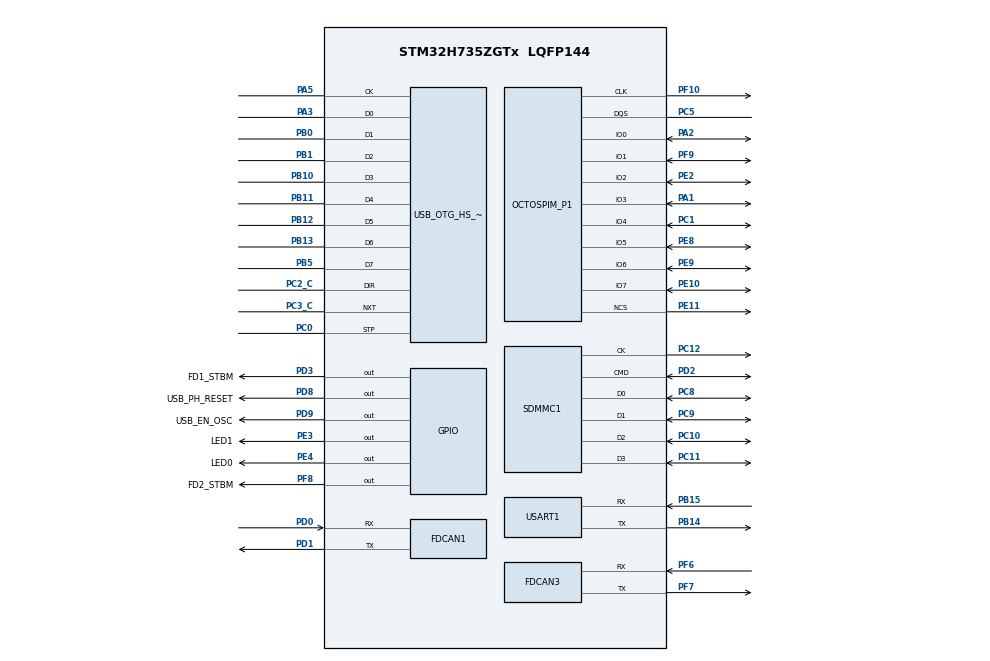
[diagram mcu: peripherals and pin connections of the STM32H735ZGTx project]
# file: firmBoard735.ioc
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CORTEX_M7.default_mode_Activation=1
Dma.Request0=USART1_TX
Dma.USART1_TX.0.Direction=DMA_MEMORY_TO_PERIPH
Dma.USART1_TX.0.EventEnable=DISABLE
Dma.USART1_TX.0.FIFOMode=DMA_FIFOMODE_DISABLE
Dma.USART1_TX.0.Instance=DMA1_Stream0
Dma.USART1_TX.0.MemDataAlignment=DMA_MDATAALIGN_BYTE
Dma.USART1_TX.0.MemInc=DMA_MINC_ENABLE
Dma.USART1_TX.0.Mode=DMA_NORMAL
Dma.USART1_TX.0.PeriphDataAlignment=DMA_PDATAALIGN_BYTE
Dma.USART1_TX.0.PeriphInc=DMA_PINC_DISABLE
Dma.USART1_TX.0.Polarity=HAL_DMAMUX_REQ_GEN_RISING
Dma.USART1_TX.0.Priority=DMA_PRIORITY_LOW
Dma.USART1_TX.0.RequestNumber=1
Dma.USART1_TX.0.SignalID=NONE
Dma.USART1_TX.0.SyncEnable=DISABLE
Dma.USART1_TX.0.SyncPolarity=HAL_DMAMUX_SYNC_NO_EVENT
Dma.USART1_TX.0.SyncRequestNumber=1
Dma.USART1_TX.0.SyncSignalID=NONE
FATFS.USE_DMA_CODE_SD=1
FATFS._FS_NORTC=0
FATFS._USE_FASTSEEK=0
FATFS._USE_LFN=1
FATFS._USE_MKFS=0
FDCAN1.CalculateBaudRateNominal=500000
FDCAN1.CalculateTimeBitNominal=2000
FDCAN1.CalculateTimeQuantumNominal=125.0
FDCAN1.Mode=FDCAN_MODE_BUS_MONITORING
FDCAN1.NominalPrescaler=12
FDCAN1.NominalSyncJumpWidth=2
FDCAN1.NominalTimeSeg1=13
FDCAN1.NominalTimeSeg2=2
FDCAN1.RxFifo0ElmtsNbr=64
FDCAN1.StdFiltersNbr=0
FDCAN1.TxFifoQueueElmtsNbr=0
FDCAN3.AutoRetransmission=ENABLE
FDCAN3.CalculateBaudRateNominal=6000000
FDCAN3.CalculateTimeBitNominal=166
FDCAN3.CalculateTimeQuantumNominal=10.416666666666666
FDCAN3.DataTimeSeg1=1
FDCAN3.DataTimeSeg2=1
FDCAN3.MessageRAMOffset=256
FDCAN3.Mode=FDCAN_MODE_NORMAL
FDCAN3.NominalPrescaler=1
FDCAN3.NominalTimeSeg1=13
FDCAN3.NominalTimeSeg2=2
FDCAN3.RxFifo0ElmtsNbr=1
FDCAN3.StdFiltersNbr=1
FDCAN3.TxFifoQueueElmtsNbr=1
Mcu.Family=STM32H7
Mcu.Name=STM32H735ZGTx
Mcu.Package=LQFP144
NVIC.DMA1_Stream0_IRQn=true\:0\:0\:false\:false\:true\:false\:true\:true
NVIC.OTG_HS_EP1_IN_IRQn=true\:0\:0\:false\:false\:true\:true\:true\:true
NVIC.OTG_HS_EP1_OUT_IRQn=true\:0\:0\:false\:false\:true\:true\:true\:true
NVIC.OTG_HS_IRQn=true\:0\:0\:false\:false\:true\:true\:true\:true
NVIC.PriorityGroup=NVIC_PRIORITYGROUP_4
NVIC.SDMMC1_IRQn=true\:0\:0\:false\:false\:true\:true\:true\:true
NVIC.USART1_IRQn=true\:0\:0\:false\:false\:true\:true\:true\:true
OCTOSPI1.AccessTime=6
OCTOSPI1.ChipSelectBoundary=0
OCTOSPI1.ChipSelectHighTime=8
OCTOSPI1.ClockPrescaler=11
OCTOSPI1.DelayBlockBypass=HAL_OSPI_DELAY_BLOCK_USED
OCTOSPI1.DelayHoldQuarterCycle=HAL_OSPI_DHQC_ENABLE
OCTOSPI1.DeviceSize=23
OCTOSPI1.FifoThreshold=4
OCTOSPI1.LatencyMode=HAL_OSPI_FIXED_LATENCY
OCTOSPI1.RWRecoveryTime=3
OCTOSPI1.Refresh=99
OCTOSPI1.WriteZeroLatency=HAL_OSPI_LATENCY_ON_WRITE
PA1.Mode=OCTOSPI1_IOL_Port1L
PA1.Signal=OCTOSPIM_P1_IO3
PA13(JTMS/SWDIO).Mode=JTAG_5_pins
PA13(JTMS/SWDIO).Signal=DEBUG_JTMS-SWDIO
PA14(JTCK/SWCLK).Mode=JTAG_5_pins
PA14(JTCK/SWCLK).Signal=DEBUG_JTCK-SWCLK
PA15(JTDI).Mode=JTAG_5_pins
PA15(JTDI).Signal=DEBUG_JTDI
PA2.Mode=OCTOSPI1_IOL_Port1L
PA2.Signal=OCTOSPIM_P1_IO0
PA3.GPIO_Speed=GPIO_SPEED_FREQ_VERY_HIGH
PA3.Mode=Device_HS
PA3.Signal=USB_OTG_HS_ULPI_D0
PA5.GPIO_Speed=GPIO_SPEED_FREQ_VERY_HIGH
PA5.Mode=Device_HS
PA5.Signal=USB_OTG_HS_ULPI_CK
PB0.GPIO_Speed=GPIO_SPEED_FREQ_VERY_HIGH
PB0.Mode=Device_HS
PB0.Signal=USB_OTG_HS_ULPI_D1
PB1.GPIO_Speed=GPIO_SPEED_FREQ_VERY_HIGH
PB1.GPIO_Speed_Only_High=GPIO_SPEED_FREQ_VERY_HIGH
PB1.Mode=Device_HS
PB1.Signal=USB_OTG_HS_ULPI_D2
PB10.GPIO_Speed=GPIO_SPEED_FREQ_VERY_HIGH
PB10.Mode=Device_HS
PB10.Signal=USB_OTG_HS_ULPI_D3
PB11.GPIO_Speed=GPIO_SPEED_FREQ_VERY_HIGH
PB11.Mode=Device_HS
PB11.Signal=USB_OTG_HS_ULPI_D4
PB12.GPIO_Speed=GPIO_SPEED_FREQ_VERY_HIGH
PB12.Mode=Device_HS
PB12.Signal=USB_OTG_HS_ULPI_D5
PB13.GPIO_Speed=GPIO_SPEED_FREQ_VERY_HIGH
PB13.Mode=Device_HS
PB13.Signal=USB_OTG_HS_ULPI_D6
PB14.Mode=Asynchronous
PB14.Signal=USART1_TX
PB15.Mode=Asynchronous
PB15.Signal=USART1_RX
PB3(JTDO/TRACESWO).Mode=JTAG_5_pins
PB3(JTDO/TRACESWO).Signal=DEBUG_JTDO-SWO
PB4(NJTRST).Mode=JTAG_5_pins
PB4(NJTRST).Signal=DEBUG_JTRST
PB5.GPIO_Speed=GPIO_SPEED_FREQ_VERY_HIGH
PB5.Mode=Device_HS
PB5.Signal=USB_OTG_HS_ULPI_D7
PC0.GPIO_Speed=GPIO_SPEED_FREQ_VERY_HIGH
PC0.Mode=Device_HS
PC0.Signal=USB_OTG_HS_ULPI_STP
PC1.Mode=OCTOSPI1_IOH_Port1H
PC1.Signal=OCTOSPIM_P1_IO4
PC10.Mode=SD_4_bits_Wide_bus
PC10.Signal=SDMMC1_D2
PC11.Mode=SD_4_bits_Wide_bus
PC11.Signal=SDMMC1_D3
PC12.Mode=SD_4_bits_Wide_bus
PC12.Signal=SDMMC1_CK
PC14-OSC32_IN.Mode=LSE-External-Oscillator
PC14-OSC32_IN.Signal=RCC_OSC32_IN
PC15-OSC32_OUT.Mode=LSE-External-Oscillator
PC15-OSC32_OUT.Signal=RCC_OSC32_OUT
PC2_C.GPIO_Speed=GPIO_SPEED_FREQ_VERY_HIGH
PC2_C.Mode=Device_HS
PC2_C.Signal=USB_OTG_HS_ULPI_DIR
PC3_C.GPIO_Speed=GPIO_SPEED_FREQ_VERY_HIGH
PC3_C.Mode=Device_HS
PC3_C.Signal=USB_OTG_HS_ULPI_NXT
PC5.Mode=OCTOSPI1_Port1_DQS
PC5.Signal=OCTOSPIM_P1_DQS
PC8.Mode=SD_4_bits_Wide_bus
PC8.Signal=SDMMC1_D0
PC9.Mode=SD_4_bits_Wide_bus
PC9.Signal=SDMMC1_D1
PD0.Mode=FDCAN_Activate
PD0.Signal=FDCAN1_RX
PD1.Mode=FDCAN_Activate
PD1.Signal=FDCAN1_TX
PD2.Mode=SD_4_bits_Wide_bus
PD2.Signal=SDMMC1_CMD
PD3.GPIO_Label=FD1_STBM
PD3.Signal=GPIO_Output
PD8.GPIO_Label=USB_PH_RESET
PD8.Signal=GPIO_Output
PD9.GPIO_Label=USB_EN_OSC
PD9.Signal=GPIO_Output
PE10.Mode=OCTOSPI1_IOH_Port1H
PE10.Signal=OCTOSPIM_P1_IO7
PE11.Mode=OCTOSPI1_Port1_NCS
PE11.Signal=OCTOSPIM_P1_NCS
PE2.Mode=OCTOSPI1_IOL_Port1L
PE2.Signal=OCTOSPIM_P1_IO2
PE3.GPIO_Label=LED1
PE3.Signal=GPIO_Output
PE4.GPIO_Label=LED0
PE4.Signal=GPIO_Output
PE8.Mode=OCTOSPI1_IOH_Port1H
PE8.Signal=OCTOSPIM_P1_IO5
PE9.Mode=OCTOSPI1_IOH_Port1H
PE9.Signal=OCTOSPIM_P1_IO6
PF10.Mode=O1_P1_CLK
PF10.Signal=OCTOSPIM_P1_CLK
PF6.Mode=FDCAN_Activate
PF6.Signal=FDCAN3_RX
PF7.Mode=FDCAN_Activate
PF7.Signal=FDCAN3_TX
PF8.GPIO_Label=FD2_STBM
PF8.Signal=GPIO_Output
PF9.Mode=OCTOSPI1_IOL_Port1L
PF9.Signal=OCTOSPIM_P1_IO1
PH0-OSC_IN.Mode=HSE-External-Oscillator
PH0-OSC_IN.Signal=RCC_OSC_IN
PH1-OSC_OUT.Mode=HSE-External-Oscillator
PH1-OSC_OUT.Signal=RCC_OSC_OUT
ProjectManager.HeapSize=0x200
ProjectManager.StackSize=0x400
ProjectManager.TargetToolchain=STM32CubeIDE
RCC.ADCFreq_Value=96000000
RCC.APB1Freq_Value=132000000
RCC.APB2Freq_Value=132000000
RCC.APB3Freq_Value=132000000
RCC.APB4Freq_Value=132000000
RCC.CortexFreq_Value=528000000
RCC.D1PPRE=RCC_APB3_DIV2
RCC.D2PPRE1=RCC_APB1_DIV2
RCC.D2PPRE2=RCC_APB2_DIV2
RCC.D3PPRE=RCC_APB4_DIV2
RCC.DIVM1=1
RCC.DIVM2=1
RCC.DIVN1=66
RCC.DIVN2=24
RCC.DIVP1=1
RCC.DIVQ1=11
RCC.DIVR2=2
RCC.FDCANCLockSelection=RCC_FDCANCLKSOURCE_PLL2
RCC.HCLKFreq_Value=264000000
RCC.HPRE=RCC_HCLK_DIV2
RCC.HSE_VALUE=8000000
RCC.PLL2FRACN=0
RCC.PLL3FRACN=0
RCC.PLLFRACN=0
RCC.PLLSourceVirtual=RCC_PLLSOURCE_HSE
RCC.RTCClockSelection=RCC_RTCCLKSOURCE_LSE
RCC.SDMMC1CLockSelection=RCC_SDMMCCLKSOURCE_PLL2
RCC.SYSCLKFreq_VALUE=528000000
RCC.SYSCLKSource=RCC_SYSCLKSOURCE_PLLCLK
RCC.SupplySource=PWR_LDO_SUPPLY
RCC.USBFreq_Value=48000000
SDMMC1.ClockDiv=2
SDMMC1.HardwareFlowControl=SDMMC_HARDWARE_FLOW_CONTROL_ENABLE
USART1.VirtualMode-Asynchronous=VM_ASYNC
USB_DEVICE.CLASS_NAME_HS=CDC
USB_DEVICE.VirtualMode=Cdc
USB_DEVICE.VirtualModeHS=Cdc_HS
USB_OTG_HS.VirtualMode-Device_HS=Device_HS
VP_FATFS_VS_SDIO.Mode=SDIO
VP_MEMORYMAP_VS_MEMORYMAP.Mode=CurAppReg
VP_OCTOSPI1_VS_hyperbus.Mode=hyperbus_mode
VP_RTC_VS_RTC_Activate.Mode=RTC_Enabled
VP_USB_DEVICE_VS_USB_DEVICE_CDC_HS.Mode=CDC_HS
board=custom

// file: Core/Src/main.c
/* USER CODE BEGIN Header */
/**
  ******************************************************************************
  * @file           : main.c
  * @brief          : Main program body
  ******************************************************************************
  * @attention
  *
  * Copyright (c) 2026 STMicroelectronics.
  * All rights reserved.
  *
  * This software is licensed under terms that can be found in the LICENSE file
  * in the root directory of this software component.
  * If no LICENSE file comes with this software, it is provided AS-IS.
  *
  ******************************************************************************
  */
/* USER CODE END Header */
#include "main.h"
#include "fatfs.h"
#include "usb_device.h"

/* USER CODE BEGIN Includes */
#include <stdio.h>
#include "console.h"
#include "can_sniffer.h"
#include "sd_test.h"
#include "fatfs_test.h"
#include "hyperram_test.h"
#include "hyperram_capture.h"
#include "board_id.h"
#include "rtc_test.h"
/* USER CODE END Includes */

FDCAN_HandleTypeDef hfdcan1;
FDCAN_HandleTypeDef hfdcan3;

OSPI_HandleTypeDef hospi1;

RTC_HandleTypeDef hrtc;

SD_HandleTypeDef hsd1;

UART_HandleTypeDef huart1;
DMA_HandleTypeDef hdma_usart1_tx;

void SystemClock_Config(void);
void PeriphCommonClock_Config(void);
static void MPU_Config(void);
static void MX_GPIO_Init(void);
static void MX_DMA_Init(void);
static void MX_USART1_UART_Init(void);
static void MX_FDCAN1_Init(void);
static void MX_FDCAN3_Init(void);
static void MX_SDMMC1_SD_Init(void);
static void MX_OCTOSPI1_Init(void);
static void MX_RTC_Init(void);

int main(void)
{

  /* MPU Configuration--------------------------------------------------------*/
  MPU_Config();

  /* MCU Configuration--------------------------------------------------------*/

  /* Reset of all peripherals, Initializes the Flash interface and the Systick. */
  HAL_Init();

  /* Configure the system clock */
  SystemClock_Config();

  /* Configure the peripherals common clocks */
  PeriphCommonClock_Config();

  /* USER CODE BEGIN SysInit */

  /* Compensate high-speed GPIO output impedance across process/voltage/temperature. */
  HAL_EnableCompensationCell();

  /* USER CODE END SysInit */

  /* Initialize all configured peripherals */
  MX_GPIO_Init();
  MX_DMA_Init();
  MX_USART1_UART_Init();
  MX_FDCAN1_Init();
  MX_FDCAN3_Init();
  MX_SDMMC1_SD_Init();
  MX_FATFS_Init();
  MX_OCTOSPI1_Init();
  MX_RTC_Init();
  MX_USB_DEVICE_Init();
  /* USER CODE BEGIN 2 */
  Console_Init(&huart1);
  printf("\r\nBusAnalyzerII console ready\r\n");
  printf("CPU clock    : %lu Hz\r\n",
         (unsigned long)SystemCoreClock);
  BoardID_Init();
  BoardID_Print(&huart1);

  RTC_Test(&hrtc, &huart1);

  HyperRAM_Test_Memory();

  HyperRAM_Test_ConfigRegisters();
  HyperRAM_Test_BurstStress();

  SD_Test_ReadOnly();
  FATFS_Test_ReadOnly();
  FATFS_Test_ReadWrite();
  CAN_Sniffer_Init();
  HyperRAM_Capture_Init();

  /* USER CODE END 2 */

  /* Infinite loop */
  /* USER CODE BEGIN WHILE */
  uint32_t can_stats_tick = HAL_GetTick();
  uint64_t previous_capture_cycles = 0U;
  uint32_t previous_measured_frames = 0U;
  while (1)
  {
    /* USER CODE END WHILE */

    /* USER CODE BEGIN 3 */
	CAN_Sniffer_Process();

      HyperRAM_Capture_Process();

      uint32_t now = HAL_GetTick();

      if ((now - can_stats_tick) >= 1000U)
      {
          can_stats_tick = now;
          uint64_t total_capture_cycles =
              CAN_Sniffer_GetCaptureCycles();

          uint32_t total_measured_frames =
              CAN_Sniffer_GetMeasuredFrames();

          uint64_t delta_cycles =
              total_capture_cycles - previous_capture_cycles;

          uint32_t delta_frames =
              total_measured_frames - previous_measured_frames;

          previous_capture_cycles = total_capture_cycles;
          previous_measured_frames = total_measured_frames;

          uint32_t cycles_per_frame = 0U;

          if (delta_frames > 0U)
          {
              cycles_per_frame =
                  (uint32_t)(delta_cycles / delta_frames);
          }
          printf(
              "CAN rx=%lu hram=%lu sram=%lu drop=%lu "
              "hramErr=%lu hramLost=%lu wrap=%lu "
              "fifoLost=%lu maxFIFO=%lu errors=%lu cpf=%lu\r\n",
              (unsigned long)CAN_Sniffer_GetRxCount(),
              (unsigned long)HyperRAM_Capture_GetStoredCount(),
              (unsigned long)CAN_Sniffer_GetBufferedCount(),
              (unsigned long)CAN_Sniffer_GetDroppedCount(),
              (unsigned long)HyperRAM_Capture_GetWriteErrors(),
              (unsigned long)HyperRAM_Capture_GetWriteLostFrames(),
              (unsigned long)HyperRAM_Capture_GetWrapCount(),
              (unsigned long)CAN_Sniffer_GetFifoLostEvents(),
              (unsigned long)CAN_Sniffer_GetMaxFifoFill(),
              (unsigned long)CAN_Sniffer_GetErrorCount(),
              (unsigned long)cycles_per_frame);
      }
  }
  /* USER CODE END 3 */
}

void SystemClock_Config(void)
{
  RCC_OscInitTypeDef RCC_OscInitStruct = {0};
  RCC_ClkInitTypeDef RCC_ClkInitStruct = {0};

  /** Supply configuration update enable
  */
  HAL_PWREx_ConfigSupply(PWR_LDO_SUPPLY);

  /** Configure the main internal regulator output voltage
  */
  __HAL_PWR_VOLTAGESCALING_CONFIG(PWR_REGULATOR_VOLTAGE_SCALE0);

  while(!__HAL_PWR_GET_FLAG(PWR_FLAG_VOSRDY)) {}

  /** Configure LSE Drive Capability
  */
  HAL_PWR_EnableBkUpAccess();
  __HAL_RCC_LSEDRIVE_CONFIG(RCC_LSEDRIVE_LOW);

  /** Initializes the RCC Oscillators according to the specified parameters
  * in the RCC_OscInitTypeDef structure.
  */
  RCC_OscInitStruct.OscillatorType = RCC_OSCILLATORTYPE_HSE|RCC_OSCILLATORTYPE_LSE;
  RCC_OscInitStruct.HSEState = RCC_HSE_ON;
  RCC_OscInitStruct.LSEState = RCC_LSE_ON;
  RCC_OscInitStruct.PLL.PLLState = RCC_PLL_ON;
  RCC_OscInitStruct.PLL.PLLSource = RCC_PLLSOURCE_HSE;
  RCC_OscInitStruct.PLL.PLLM = 1;
  RCC_OscInitStruct.PLL.PLLN = 66;
  RCC_OscInitStruct.PLL.PLLP = 1;
  RCC_OscInitStruct.PLL.PLLQ = 11;
  RCC_OscInitStruct.PLL.PLLR = 2;
  RCC_OscInitStruct.PLL.PLLRGE = RCC_PLL1VCIRANGE_3;
  RCC_OscInitStruct.PLL.PLLVCOSEL = RCC_PLL1VCOWIDE;
  RCC_OscInitStruct.PLL.PLLFRACN = 0;
  if (HAL_RCC_OscConfig(&RCC_OscInitStruct) != HAL_OK)
  {
    Error_Handler();
  }

  /** Initializes the CPU, AHB and APB buses clocks
  */
  RCC_ClkInitStruct.ClockType = RCC_CLOCKTYPE_HCLK|RCC_CLOCKTYPE_SYSCLK
                              |RCC_CLOCKTYPE_PCLK1|RCC_CLOCKTYPE_PCLK2
                              |RCC_CLOCKTYPE_D3PCLK1|RCC_CLOCKTYPE_D1PCLK1;
  RCC_ClkInitStruct.SYSCLKSource = RCC_SYSCLKSOURCE_PLLCLK;
  RCC_ClkInitStruct.SYSCLKDivider = RCC_SYSCLK_DIV1;
  RCC_ClkInitStruct.AHBCLKDivider = RCC_HCLK_DIV2;
  RCC_ClkInitStruct.APB3CLKDivider = RCC_APB3_DIV2;
  RCC_ClkInitStruct.APB1CLKDivider = RCC_APB1_DIV2;
  RCC_ClkInitStruct.APB2CLKDivider = RCC_APB2_DIV2;
  RCC_ClkInitStruct.APB4CLKDivider = RCC_APB4_DIV2;

  if (HAL_RCC_ClockConfig(&RCC_ClkInitStruct, FLASH_LATENCY_3) != HAL_OK)
  {
    Error_Handler();
  }
  __HAL_RCC_PLLCLKOUT_ENABLE(RCC_PLL1_DIVQ);
}

void PeriphCommonClock_Config(void)
{
  RCC_PeriphCLKInitTypeDef PeriphClkInitStruct = {0};

  /** Initializes the peripherals clock
  */
  PeriphClkInitStruct.PeriphClockSelection = RCC_PERIPHCLK_SDMMC|RCC_PERIPHCLK_FDCAN;
  PeriphClkInitStruct.PLL2.PLL2M = 1;
  PeriphClkInitStruct.PLL2.PLL2N = 24;
  PeriphClkInitStruct.PLL2.PLL2P = 2;
  PeriphClkInitStruct.PLL2.PLL2Q = 2;
  PeriphClkInitStruct.PLL2.PLL2R = 2;
  PeriphClkInitStruct.PLL2.PLL2RGE = RCC_PLL2VCIRANGE_3;
  PeriphClkInitStruct.PLL2.PLL2VCOSEL = RCC_PLL2VCOWIDE;
  PeriphClkInitStruct.PLL2.PLL2FRACN = 0;
  PeriphClkInitStruct.SdmmcClockSelection = RCC_SDMMCCLKSOURCE_PLL2;
  PeriphClkInitStruct.FdcanClockSelection = RCC_FDCANCLKSOURCE_PLL2;
  if (HAL_RCCEx_PeriphCLKConfig(&PeriphClkInitStruct) != HAL_OK)
  {
    Error_Handler();
  }
}

static void MX_FDCAN1_Init(void)
{

  hfdcan1.Instance = FDCAN1;
  hfdcan1.Init.FrameFormat = FDCAN_FRAME_CLASSIC;
  hfdcan1.Init.Mode = FDCAN_MODE_BUS_MONITORING;
  hfdcan1.Init.AutoRetransmission = DISABLE;
  hfdcan1.Init.TransmitPause = DISABLE;
  hfdcan1.Init.ProtocolException = DISABLE;
  hfdcan1.Init.NominalPrescaler = 12;
  hfdcan1.Init.NominalSyncJumpWidth = 2;
  hfdcan1.Init.NominalTimeSeg1 = 13;
  hfdcan1.Init.NominalTimeSeg2 = 2;
  hfdcan1.Init.DataPrescaler = 1;
  hfdcan1.Init.DataSyncJumpWidth = 1;
  hfdcan1.Init.DataTimeSeg1 = 1;
  hfdcan1.Init.DataTimeSeg2 = 1;
  hfdcan1.Init.MessageRAMOffset = 0;
  hfdcan1.Init.StdFiltersNbr = 0;
  hfdcan1.Init.ExtFiltersNbr = 0;
  hfdcan1.Init.RxFifo0ElmtsNbr = 64;
  hfdcan1.Init.RxFifo0ElmtSize = FDCAN_DATA_BYTES_8;
  hfdcan1.Init.RxFifo1ElmtsNbr = 0;
  hfdcan1.Init.RxFifo1ElmtSize = FDCAN_DATA_BYTES_8;
  hfdcan1.Init.RxBuffersNbr = 0;
  hfdcan1.Init.RxBufferSize = FDCAN_DATA_BYTES_8;
  hfdcan1.Init.TxEventsNbr = 0;
  hfdcan1.Init.TxBuffersNbr = 0;
  hfdcan1.Init.TxFifoQueueElmtsNbr = 0;
  hfdcan1.Init.TxFifoQueueMode = FDCAN_TX_FIFO_OPERATION;
  hfdcan1.Init.TxElmtSize = FDCAN_DATA_BYTES_8;
  if (HAL_FDCAN_Init(&hfdcan1) != HAL_OK)
  {
    Error_Handler();
  }

}

static void MX_FDCAN3_Init(void)
{

  hfdcan3.Instance = FDCAN3;
  hfdcan3.Init.FrameFormat = FDCAN_FRAME_CLASSIC;
  hfdcan3.Init.Mode = FDCAN_MODE_NORMAL;
  hfdcan3.Init.AutoRetransmission = ENABLE;
  hfdcan3.Init.TransmitPause = DISABLE;
  hfdcan3.Init.ProtocolException = DISABLE;
  hfdcan3.Init.NominalPrescaler = 1;
  hfdcan3.Init.NominalSyncJumpWidth = 1;
  hfdcan3.Init.NominalTimeSeg1 = 13;
  hfdcan3.Init.NominalTimeSeg2 = 2;
  hfdcan3.Init.DataPrescaler = 1;
  hfdcan3.Init.DataSyncJumpWidth = 1;
  hfdcan3.Init.DataTimeSeg1 = 1;
  hfdcan3.Init.DataTimeSeg2 = 1;
  hfdcan3.Init.MessageRAMOffset = 256;
  hfdcan3.Init.StdFiltersNbr = 1;
  hfdcan3.Init.ExtFiltersNbr = 0;
  hfdcan3.Init.RxFifo0ElmtsNbr = 1;
  hfdcan3.Init.RxFifo0ElmtSize = FDCAN_DATA_BYTES_8;
  hfdcan3.Init.RxFifo1ElmtsNbr = 0;
  hfdcan3.Init.RxFifo1ElmtSize = FDCAN_DATA_BYTES_8;
  hfdcan3.Init.RxBuffersNbr = 0;
  hfdcan3.Init.RxBufferSize = FDCAN_DATA_BYTES_8;
  hfdcan3.Init.TxEventsNbr = 0;
  hfdcan3.Init.TxBuffersNbr = 0;
  hfdcan3.Init.TxFifoQueueElmtsNbr = 1;
  hfdcan3.Init.TxFifoQueueMode = FDCAN_TX_FIFO_OPERATION;
  hfdcan3.Init.TxElmtSize = FDCAN_DATA_BYTES_8;
  if (HAL_FDCAN_Init(&hfdcan3) != HAL_OK)
  {
    Error_Handler();
  }

}

static void MX_OCTOSPI1_Init(void)
{

  OSPIM_CfgTypeDef sOspiManagerCfg = {0};
  OSPI_HyperbusCfgTypeDef sHyperBusCfg = {0};

  /* USER CODE BEGIN OCTOSPI1_Init 1 */

   sOspiManagerCfg.Req2AckTime = 1;

  /* USER CODE END OCTOSPI1_Init 1 */
  /* OCTOSPI1 parameter configuration*/
  hospi1.Instance = OCTOSPI1;
  hospi1.Init.FifoThreshold = 4;
  hospi1.Init.DualQuad = HAL_OSPI_DUALQUAD_DISABLE;
  hospi1.Init.MemoryType = HAL_OSPI_MEMTYPE_HYPERBUS;
  hospi1.Init.DeviceSize = 23;
  hospi1.Init.ChipSelectHighTime = 8;
  hospi1.Init.FreeRunningClock = HAL_OSPI_FREERUNCLK_DISABLE;
  hospi1.Init.ClockMode = HAL_OSPI_CLOCK_MODE_0;
  hospi1.Init.WrapSize = HAL_OSPI_WRAP_NOT_SUPPORTED;
  hospi1.Init.ClockPrescaler = 11;
  hospi1.Init.SampleShifting = HAL_OSPI_SAMPLE_SHIFTING_NONE;
  hospi1.Init.DelayHoldQuarterCycle = HAL_OSPI_DHQC_ENABLE;
  hospi1.Init.ChipSelectBoundary = 0;
  hospi1.Init.DelayBlockBypass = HAL_OSPI_DELAY_BLOCK_USED;
  hospi1.Init.MaxTran = 0;
  hospi1.Init.Refresh = 99;
  if (HAL_OSPI_Init(&hospi1) != HAL_OK)
  {
    Error_Handler();
  }
  sOspiManagerCfg.ClkPort = 1;
  sOspiManagerCfg.DQSPort = 1;
  sOspiManagerCfg.NCSPort = 1;
  sOspiManagerCfg.IOLowPort = HAL_OSPIM_IOPORT_1_LOW;
  sOspiManagerCfg.IOHighPort = HAL_OSPIM_IOPORT_1_HIGH;
  if (HAL_OSPIM_Config(&hospi1, &sOspiManagerCfg, HAL_OSPI_TIMEOUT_DEFAULT_VALUE) != HAL_OK)
  {
    Error_Handler();
  }
  sHyperBusCfg.RWRecoveryTime = 3;
  sHyperBusCfg.AccessTime = 6;
  sHyperBusCfg.WriteZeroLatency = HAL_OSPI_LATENCY_ON_WRITE;
  sHyperBusCfg.LatencyMode = HAL_OSPI_FIXED_LATENCY;
  if (HAL_OSPI_HyperbusCfg(&hospi1, &sHyperBusCfg, HAL_OSPI_TIMEOUT_DEFAULT_VALUE) != HAL_OK)
  {
    Error_Handler();
  }

}

static void MX_RTC_Init(void)
{

  /** Initialize RTC Only
  */
  hrtc.Instance = RTC;
  hrtc.Init.HourFormat = RTC_HOURFORMAT_24;
  hrtc.Init.AsynchPrediv = 127;
  hrtc.Init.SynchPrediv = 255;
  hrtc.Init.OutPut = RTC_OUTPUT_DISABLE;
  hrtc.Init.OutPutPolarity = RTC_OUTPUT_POLARITY_HIGH;
  hrtc.Init.OutPutType = RTC_OUTPUT_TYPE_OPENDRAIN;
  hrtc.Init.OutPutRemap = RTC_OUTPUT_REMAP_NONE;
  if (HAL_RTC_Init(&hrtc) != HAL_OK)
  {
    Error_Handler();
  }

}

static void MX_SDMMC1_SD_Init(void)
{

  hsd1.Instance = SDMMC1;
  hsd1.Init.ClockEdge = SDMMC_CLOCK_EDGE_RISING;
  hsd1.Init.ClockPowerSave = SDMMC_CLOCK_POWER_SAVE_DISABLE;
  hsd1.Init.BusWide = SDMMC_BUS_WIDE_4B;
  hsd1.Init.HardwareFlowControl = SDMMC_HARDWARE_FLOW_CONTROL_ENABLE;
  hsd1.Init.ClockDiv = 2;
  if (HAL_SD_Init(&hsd1) != HAL_OK)
  {
    Error_Handler();
  }

}

static void MX_USART1_UART_Init(void)
{

  huart1.Instance = USART1;
  huart1.Init.BaudRate = 115200;
  huart1.Init.WordLength = UART_WORDLENGTH_8B;
  huart1.Init.StopBits = UART_STOPBITS_1;
  huart1.Init.Parity = UART_PARITY_NONE;
  huart1.Init.Mode = UART_MODE_TX_RX;
  huart1.Init.HwFlowCtl = UART_HWCONTROL_NONE;
  huart1.Init.OverSampling = UART_OVERSAMPLING_16;
  huart1.Init.OneBitSampling = UART_ONE_BIT_SAMPLE_DISABLE;
  huart1.Init.ClockPrescaler = UART_PRESCALER_DIV1;
  huart1.AdvancedInit.AdvFeatureInit = UART_ADVFEATURE_NO_INIT;
  if (HAL_UART_Init(&huart1) != HAL_OK)
  {
    Error_Handler();
  }
  if (HAL_UARTEx_SetTxFifoThreshold(&huart1, UART_TXFIFO_THRESHOLD_1_8) != HAL_OK)
  {
    Error_Handler();
  }
  if (HAL_UARTEx_SetRxFifoThreshold(&huart1, UART_RXFIFO_THRESHOLD_1_8) != HAL_OK)
  {
    Error_Handler();
  }
  if (HAL_UARTEx_DisableFifoMode(&huart1) != HAL_OK)
  {
    Error_Handler();
  }

}

static void MX_DMA_Init(void)
{

  /* DMA controller clock enable */
  __HAL_RCC_DMA1_CLK_ENABLE();

  /* DMA interrupt init */
  /* DMA1_Stream0_IRQn interrupt configuration */
  HAL_NVIC_SetPriority(DMA1_Stream0_IRQn, 0, 0);
  HAL_NVIC_EnableIRQ(DMA1_Stream0_IRQn);

}

static void MX_GPIO_Init(void)
{
  GPIO_InitTypeDef GPIO_InitStruct = {0};

  /* GPIO Ports Clock Enable */
  __HAL_RCC_GPIOE_CLK_ENABLE();
  __HAL_RCC_GPIOC_CLK_ENABLE();
  __HAL_RCC_GPIOF_CLK_ENABLE();
  __HAL_RCC_GPIOH_CLK_ENABLE();
  __HAL_RCC_GPIOA_CLK_ENABLE();
  __HAL_RCC_GPIOB_CLK_ENABLE();
  __HAL_RCC_GPIOD_CLK_ENABLE();

  /* USB3300 RESET is active high; hold it until USB startup. */
  HAL_GPIO_WritePin(USB_PHY_RESET_GPIO_Port, USB_PHY_RESET_Pin, GPIO_PIN_SET);

  /*Configure GPIO pin Output Level */
  HAL_GPIO_WritePin(GPIOE, LED1_Pin|LED0_Pin, GPIO_PIN_RESET);

  /*Configure GPIO pin Output Level */
  HAL_GPIO_WritePin(FD2_STBM_GPIO_Port, FD2_STBM_Pin, GPIO_PIN_RESET);

  /*Configure GPIO pin Output Level */
  HAL_GPIO_WritePin(FD1_STBM_GPIO_Port, FD1_STBM_Pin, GPIO_PIN_RESET);

  /*Configure GPIO pins : LED1_Pin LED0_Pin */
  GPIO_InitStruct.Pin = LED1_Pin|LED0_Pin;
  GPIO_InitStruct.Mode = GPIO_MODE_OUTPUT_PP;
  GPIO_InitStruct.Pull = GPIO_NOPULL;
  GPIO_InitStruct.Speed = GPIO_SPEED_FREQ_LOW;
  HAL_GPIO_Init(GPIOE, &GPIO_InitStruct);

  /*Configure GPIO pin : FD2_STBM_Pin */
  GPIO_InitStruct.Pin = FD2_STBM_Pin;
  GPIO_InitStruct.Mode = GPIO_MODE_OUTPUT_PP;
  GPIO_InitStruct.Pull = GPIO_NOPULL;
  GPIO_InitStruct.Speed = GPIO_SPEED_FREQ_LOW;
  HAL_GPIO_Init(FD2_STBM_GPIO_Port, &GPIO_InitStruct);

  /*Configure GPIO pin : USB_PHY_RESET_Pin (PC7, MCU pin 94, via 33) */
  GPIO_InitStruct.Pin = USB_PHY_RESET_Pin;
  GPIO_InitStruct.Mode = GPIO_MODE_OUTPUT_PP;
  GPIO_InitStruct.Pull = GPIO_NOPULL;
  GPIO_InitStruct.Speed = GPIO_SPEED_FREQ_LOW;
  HAL_GPIO_Init(USB_PHY_RESET_GPIO_Port, &GPIO_InitStruct);

  /*Configure GPIO pin : FD1_STBM_Pin */
  GPIO_InitStruct.Pin = FD1_STBM_Pin;
  GPIO_InitStruct.Mode = GPIO_MODE_OUTPUT_PP;
  GPIO_InitStruct.Pull = GPIO_NOPULL;
  GPIO_InitStruct.Speed = GPIO_SPEED_FREQ_LOW;
  HAL_GPIO_Init(FD1_STBM_GPIO_Port, &GPIO_InitStruct);

}

 /* MPU Configuration */

void MPU_Config(void)
{
  MPU_Region_InitTypeDef MPU_InitStruct = {0};

  /* Disables the MPU */
  HAL_MPU_Disable();

  /** Initializes and configures the Region and the memory to be protected
  */
  MPU_InitStruct.Enable = MPU_REGION_ENABLE;
  MPU_InitStruct.Number = MPU_REGION_NUMBER0;
  MPU_InitStruct.BaseAddress = 0x0;
  MPU_InitStruct.Size = MPU_REGION_SIZE_4GB;
  MPU_InitStruct.SubRegionDisable = 0x87;
  MPU_InitStruct.TypeExtField = MPU_TEX_LEVEL0;
  MPU_InitStruct.AccessPermission = MPU_REGION_NO_ACCESS;
  MPU_InitStruct.DisableExec = MPU_INSTRUCTION_ACCESS_DISABLE;
  MPU_InitStruct.IsShareable = MPU_ACCESS_SHAREABLE;
  MPU_InitStruct.IsCacheable = MPU_ACCESS_NOT_CACHEABLE;
  MPU_InitStruct.IsBufferable = MPU_ACCESS_NOT_BUFFERABLE;

  HAL_MPU_ConfigRegion(&MPU_InitStruct);
  /* Enables the MPU */
  HAL_MPU_Enable(MPU_PRIVILEGED_DEFAULT);

}

void Error_Handler(void)
{
  __disable_irq();
  while (1)
  {
  }
}
